AUTOSAR XML (schema 314)
package /ComponentType
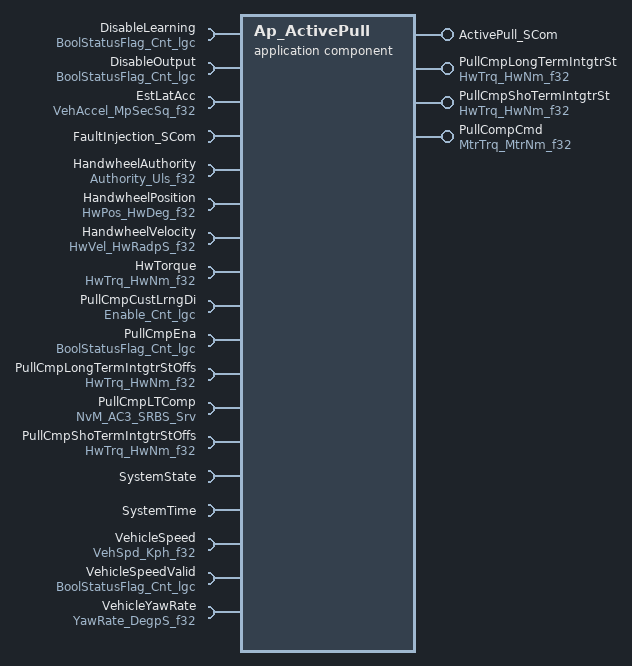
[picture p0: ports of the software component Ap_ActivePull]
  application software component type Ap_ActivePull
    4 x provide port:
      ActivePull_SCom: provided-interface=ActivePull_SCom
        provided-com-specs:
          operation=ReadParam, queue-length=1
          operation=Reset, queue-length=1
          operation=SetLTComp, queue-length=1
          operation=SetSTComp, queue-length=1
      PullCmpLongTermIntgtrSt: unqueued-sender-com-spec{data-element=HwNm_f32, can-invalidate=false, init-value=D_ZERO_ULS_F32}, provided-interface=HwTrq_HwNm_f32
      PullCmpShoTermIntgtrSt: unqueued-sender-com-spec{data-element=HwNm_f32, can-invalidate=false, init-value=D_ZERO_ULS_F32}, provided-interface=HwTrq_HwNm_f32
      PullCompCmd: unqueued-sender-com-spec{data-element=MtrNm_f32, can-invalidate=false, init-value=D_ZERO_ULS_F32}, provided-interface=MtrTrq_MtrNm_f32
    18 x require port:
      DisableLearning: unqueued-receiver-com-spec{data-element=Cnt_lgc, init-value=D_FALSE_CNT_LGC}, required-interface=BoolStatusFlag_Cnt_lgc
      DisableOutput: unqueued-receiver-com-spec{data-element=Cnt_lgc, init-value=D_FALSE_CNT_LGC}, required-interface=BoolStatusFlag_Cnt_lgc
      EstLatAcc: unqueued-receiver-com-spec{data-element=MpSecSq_f32, init-value=D_ZERO_ULS_F32}, required-interface=VehAccel_MpSecSq_f32
      FaultInjection_SCom: client-com-spec=FltInjection, required-interface=FaultInjection_SCom
      HandwheelAuthority: unqueued-receiver-com-spec{data-element=Uls_f32, init-value=D_ZERO_ULS_F32}, required-interface=Authority_Uls_f32
      HandwheelPosition: unqueued-receiver-com-spec{data-element=HwDeg_f32, init-value=D_ZERO_ULS_F32}, required-interface=HwPos_HwDeg_f32
      HandwheelVelocity: unqueued-receiver-com-spec{data-element=HwRadpS_f32, init-value=D_ZERO_ULS_F32}, required-interface=HwVel_HwRadpS_f32
      HwTorque: unqueued-receiver-com-spec{data-element=HwNm_f32, init-value=D_ZERO_ULS_F32}, required-interface=HwTrq_HwNm_f32
      PullCmpCustLrngDi: unqueued-receiver-com-spec{data-element=Cnt_lgc, init-value=D_FALSE_CNT_LGC}, required-interface=Enable_Cnt_lgc
      PullCmpEna: unqueued-receiver-com-spec{data-element=Cnt_lgc, init-value=D_TRUE_CNT_LGC}, required-interface=BoolStatusFlag_Cnt_lgc
      PullCmpLongTermIntgtrStOffs: unqueued-receiver-com-spec{data-element=HwNm_f32, init-value=D_ZERO_ULS_F32}, required-interface=HwTrq_HwNm_f32
      PullCmpLTComp: required-com-specs=[EraseBlock, GetErrorStatus, InvalidateNvBlock, ReadBlock, SetRamBlockStatus, WriteBlock], required-interface=NvM_AC3_SRBS_Srv
      PullCmpShoTermIntgtrStOffs: unqueued-receiver-com-spec{data-element=HwNm_f32, init-value=D_ZERO_ULS_F32}, required-interface=HwTrq_HwNm_f32
      SystemState: required-interface=SystemState
      SystemTime: required-interface=SystemTime
        required-com-specs:
          DtrmnElapsedTime_mS_u16
          DtrmnElapsedTime_mS_u32
          DtrmnElapsedTime_uS_u16
          DtrmnElapsedTime_uS_u32
          GetSystemTime_mS_u32
          GetSystemTime_uS_u32
      VehicleSpeed: unqueued-receiver-com-spec{data-element=Kph_f32, init-value=D_ZERO_ULS_F32}, required-interface=VehSpd_Kph_f32
      VehicleSpeedValid: unqueued-receiver-com-spec{data-element=Cnt_lgc, init-value=D_FALSE_CNT_LGC}, required-interface=BoolStatusFlag_Cnt_lgc
      VehicleYawRate: unqueued-receiver-com-spec{data-element=DegpS_f32, init-value=D_ZERO_ULS_F32}, required-interface=YawRate_DegpS_f32
  internal behavior Ap_ActivePull_InternalBehavior: component=Ap_ActivePull
    4 x timing event:
      ActivePull_Init1_InitEvent: start-on-event=ActivePull_Init1, period=0
      TMT_ActivePull_Per1: mode-dependency=dependent-on-mode=[SystemState.Mode.DISABLE, SystemState.Mode.OFF, SystemState.Mode.WARMINIT], start-on-event=ActivePull_Per1, period=0.002
      TMT_ActivePull_Per2: mode-dependency=dependent-on-mode=SystemState.Mode.OFF, start-on-event=ActivePull_Per2, period=0.002
      TMT_ActivePull_Per3: mode-dependency=dependent-on-mode=[SystemState.Mode.DISABLE, SystemState.Mode.OFF, SystemState.Mode.WARMINIT], start-on-event=ActivePull_Per3, period=0.1
    4 x operation invoked event:
      OIT_ActivePull_SCom_ReadParam_ActivePull_SCom_ReadParam: start-on-event=ActivePull_SCom_ReadParam, operation=ActivePull_SCom.ReadParam
      OIT_ActivePull_SCom_Reset_ActivePull_SCom_Reset: start-on-event=ActivePull_SCom_Reset, operation=ActivePull_SCom.Reset
      OIT_ActivePull_SCom_SetLTComp_ActivePull_SCom_SetLTComp: start-on-event=ActivePull_SCom_SetLTComp, operation=ActivePull_SCom.SetLTComp
      OIT_ActivePull_SCom_SetSTComp_ActivePull_SCom_SetSTComp: start-on-event=ActivePull_SCom_SetSTComp, operation=ActivePull_SCom.SetSTComp
    mode switch event MST_ActivePull_Trns1_0: start-on-event=ActivePull_Trns1, activation=ENTRY, mode=SystemState.Mode.OPERATE
    mode switch event MST_ActivePull_Trns2_0: start-on-event=ActivePull_Trns2, activation=ENTRY, mode=SystemState.Mode.OFF
    per instance memory PullCmpLTComp_HwNm_f32: type=Float, type-definition=/DataType/Float
    port-api-options:
      enable-take-address=false, indirect-api=false, port=ActivePull_SCom
      enable-take-address=false, indirect-api=false, port=DisableLearning
      enable-take-address=false, indirect-api=false, port=DisableOutput
      enable-take-address=false, indirect-api=false, port=EstLatAcc
      enable-take-address=false, indirect-api=false, port=FaultInjection_SCom
      enable-take-address=false, indirect-api=false, port=HandwheelAuthority
      enable-take-address=false, indirect-api=false, port=HandwheelPosition
      enable-take-address=false, indirect-api=false, port=HandwheelVelocity
      enable-take-address=false, indirect-api=false, port=HwTorque
      enable-take-address=false, indirect-api=false, port=PullCmpCustLrngDi
      enable-take-address=false, indirect-api=false, port=PullCmpEna
      enable-take-address=false, indirect-api=false, port=PullCmpLongTermIntgtrSt
      enable-take-address=false, indirect-api=false, port=PullCmpLongTermIntgtrStOffs
      enable-take-address=false, indirect-api=false, port=PullCmpLTComp
      enable-take-address=false, indirect-api=false, port=PullCmpShoTermIntgtrSt
      enable-take-address=false, indirect-api=false, port=PullCmpShoTermIntgtrStOffs
      enable-take-address=false, indirect-api=false, port=PullCompCmd
      enable-take-address=false, indirect-api=false, port=SystemState
      enable-take-address=false, indirect-api=false, port=SystemTime
      enable-take-address=false, indirect-api=false, port=VehicleSpeed
      enable-take-address=false, indirect-api=false, port=VehicleSpeedValid
      enable-take-address=false, indirect-api=false, port=VehicleYawRate
    10 x runnable:
      ActivePull_Init1
      ActivePull_Per1
        13 x data read access:
          READ_DisableLearning_Cnt_lgc: data-element=DisableLearning.Cnt_lgc
          READ_DisableOutput_Cnt_lgc: data-element=DisableOutput.Cnt_lgc
          READ_EstLatAcc_MpSecSq_f32: data-element=EstLatAcc.MpSecSq_f32
          READ_HandwheelAuthority_Uls_f32: data-element=HandwheelAuthority.Uls_f32
          READ_HandwheelPosition_HwDeg_f32: data-element=HandwheelPosition.HwDeg_f32
          READ_HandwheelVelocity_HwRadpS_f32: data-element=HandwheelVelocity.HwRadpS_f32
          READ_HwTorque_HwNm_f32: data-element=HwTorque.HwNm_f32
          READ_PullCmpCustLrngDi_Cnt_lgc: data-element=PullCmpCustLrngDi.Cnt_lgc
          READ_PullCmpEna_Cnt_lgc: data-element=PullCmpEna.Cnt_lgc
          READ_PullCmpShoTermIntgtrStOffs_HwNm_f32: data-element=PullCmpShoTermIntgtrStOffs.HwNm_f32
          READ_VehicleSpeed_Kph_f32: data-element=VehicleSpeed.Kph_f32
          READ_VehicleSpeedValid_Cnt_lgc: data-element=VehicleSpeedValid.Cnt_lgc
          READ_VehicleYawRate_DegpS_f32: data-element=VehicleYawRate.DegpS_f32
        data write access WRITE_PullCmpShoTermIntgtrSt_HwNm_f32: data-element=PullCmpShoTermIntgtrSt.HwNm_f32
        sync call SC_SystemTime_DtrmnElapsedTime_mS_u32: operation=SystemTime.DtrmnElapsedTime_mS_u32, timeout=0
        sync call SC_SystemTime_GetSystemTime_mS_u32: operation=SystemTime.GetSystemTime_mS_u32, timeout=0
      ActivePull_Per2
        5 x data read access:
          READ_DisableOutput_Cnt_lgc: data-element=DisableOutput.Cnt_lgc
          READ_PullCmpEna_Cnt_lgc: data-element=PullCmpEna.Cnt_lgc
          READ_PullCmpLongTermIntgtrStOffs_HwNm_f32: data-element=PullCmpLongTermIntgtrStOffs.HwNm_f32
          READ_PullCmpShoTermIntgtrStOffs_HwNm_f32: data-element=PullCmpShoTermIntgtrStOffs.HwNm_f32
          READ_VehicleSpeed_Kph_f32: data-element=VehicleSpeed.Kph_f32
        data write access WRITE_PullCompCmd_MtrNm_f32: data-element=PullCompCmd.MtrNm_f32
        sync call SC_FaultInjection_SCom_FltInjection: operation=FaultInjection_SCom.FltInjection, timeout=0
      ActivePull_Per3
        4 x data read access:
          READ_HwTorque_HwNm_f32: data-element=HwTorque.HwNm_f32
          READ_PullCmpEna_Cnt_lgc: data-element=PullCmpEna.Cnt_lgc
          READ_PullCmpLongTermIntgtrStOffs_HwNm_f32: data-element=PullCmpLongTermIntgtrStOffs.HwNm_f32
          READ_VehicleSpeed_Kph_f32: data-element=VehicleSpeed.Kph_f32
        data write access WRITE_PullCmpLongTermIntgtrSt_HwNm_f32: data-element=PullCmpLongTermIntgtrSt.HwNm_f32
      ActivePull_SCom_ReadParam
      ActivePull_SCom_Reset
      ActivePull_SCom_SetLTComp
      ActivePull_SCom_SetSTComp
      ActivePull_Trns1
        sync call SC_SystemTime_GetSystemTime_mS_u32: operation=SystemTime.GetSystemTime_mS_u32, timeout=0
      ActivePull_Trns2
        sync call SC_PullCmpLTComp_SetRamBlockStatus: operation=PullCmpLTComp.SetRamBlockStatus, timeout=0
    service-needss:
      swc nv block needs PullCmpLTComp: n-data-sets=0, readonly=false, reliability=LOW, resistant-to-changed-sw=false, restore-at-start=false, write-only-once=false, writing-frequency=0, writing-priority=LOW, mirror-block=PullCmpLTComp_HwNm_f32
  swc implementation Ap_ActivePull_Implementation: behavior=Ap_ActivePull_InternalBehavior
    code-descriptors:
      code Code: type=SRC
